VERSION ""

NS_ :

BS_:

BU_: Vector__XXX

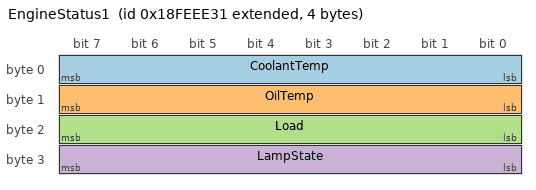
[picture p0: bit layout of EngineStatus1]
BO_ 2566843953 EngineStatus1: 4 Vector__XXX
 SG_ CoolantTemp : 0|8@1+ (1,-40) [0|210] "degC" Vector__XXX
 SG_ OilTemp : 8|8@1+ (1,-40) [0|210] "degC" Vector__XXX
 SG_ Load : 16|8@1+ (0.4,0) [0|100] "%" Vector__XXX
 SG_ LampState : 24|8@1+ (1,0) [0|255] "" Vector__XXX

BO_ 2565866545 EngineSpeed1: 4 Vector__XXX
 SG_ EngineSpeed : 8|16@1+ (0.125,0) [0|8031.875] "rpm" Vector__XXX
 SG_ TorqueMode : 24|8@1+ (1,0) [0|255] "" Vector__XXX
